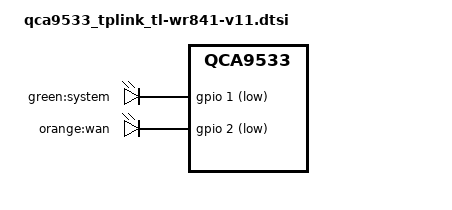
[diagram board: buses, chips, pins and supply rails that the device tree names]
// SPDX-License-Identifier: GPL-2.0-or-later OR MIT

#include "qca9533_tplink_tl-wr841.dtsi"

/ {
	aliases {
		led-boot = &led_system;
		led-failsafe = &led_system;
		led-running = &led_system;
		led-upgrade = &led_system;
	};
};

&leds {
	led_system: system {
		label = "green:system";
		gpios = <&gpio 1 GPIO_ACTIVE_LOW>;
	};

	wan_orange {
		label = "orange:wan";
		gpios = <&gpio 2 GPIO_ACTIVE_LOW>;
	};
};
